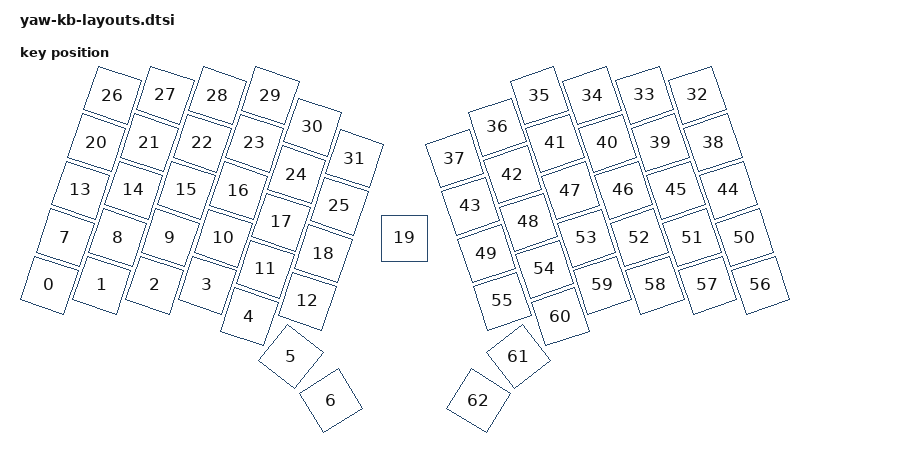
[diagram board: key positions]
#include <physical_layouts.dtsi>

/ {
    physical_layout0: physical_layout_0 {
        compatible = "zmk,physical-layout";
        display-name = "LAYOUT";

        kscan = <&kscan0>;
        transform = <&matrix_transform0>;

        keys  //                     w   h    x    y     rot    rx    ry
            = <&key_physical_attrs 100 100    0  380    1843    50   430>
            , <&key_physical_attrs 100 100  105  380    1843   155   430>
            , <&key_physical_attrs 100 100  211  380    1843   261   430>
            , <&key_physical_attrs 100 100  316  380    1843   366   431>
            , <&key_physical_attrs 100 100  400  443    1843   450   493>
            , <&key_physical_attrs 100 100  484  523    3844   534   573>
            , <&key_physical_attrs 100 100  564  611 (-3156)   614   661>
            , <&key_physical_attrs 100 100   32  285    1843    82   335>
            , <&key_physical_attrs 100 100  137  285    1843   187   335>
            , <&key_physical_attrs 100 100  242  285    1843   292   335>
            , <&key_physical_attrs 100 100  348  286    1843   398   336>
            , <&key_physical_attrs 100 100  432  348    1843   482   398>
            , <&key_physical_attrs 100 100  516  412    1843   566   462>
            , <&key_physical_attrs 100 100   63  190    1843   113   240>
            , <&key_physical_attrs 100 100  169  190    1843   219   240>
            , <&key_physical_attrs 100 100  274  190    1843   324   240>
            , <&key_physical_attrs 100 100  379  191    1843   429   241>
            , <&key_physical_attrs 100 100  464  254    1843   514   304>
            , <&key_physical_attrs 100 100  548  317    1843   598   367>
            , <&key_physical_attrs 100 100  711  286       0   761   336>
            , <&key_physical_attrs 100 100   95   95    1843   145   145>
            , <&key_physical_attrs 100 100  200   95    1843   250   145>
            , <&key_physical_attrs 100 100  306   96    1843   356   146>
            , <&key_physical_attrs 100 100  411   96    1843   461   146>
            , <&key_physical_attrs 100 100  495  159    1843   545   209>
            , <&key_physical_attrs 100 100  580  222    1843   630   272>
            , <&key_physical_attrs 100 100  127    0    1843   176    50>
            , <&key_physical_attrs 100 100  232    0    1843   282    50>
            , <&key_physical_attrs 100 100  337    1    1843   387    51>
            , <&key_physical_attrs 100 100  442    1    1843   492    51>
            , <&key_physical_attrs 100 100  527   64    1843   577   114>
            , <&key_physical_attrs 100 100  611  127    1843   661   177>
            , <&key_physical_attrs 100 100 1296    0 (-1843)  1346    50>
            , <&key_physical_attrs 100 100 1191    0 (-1843)  1241    50>
            , <&key_physical_attrs 100 100 1086    1 (-1843)  1136    51>
            , <&key_physical_attrs 100 100  980    1 (-1843)  1030    51>
            , <&key_physical_attrs 100 100  896   64 (-1843)   946   114>
            , <&key_physical_attrs 100 100  811  127 (-1843)   861   177>
            , <&key_physical_attrs 100 100 1328   95 (-1843)  1378   145>
            , <&key_physical_attrs 100 100 1222   95 (-1843)  1272   145>
            , <&key_physical_attrs 100 100 1117   96 (-1843)  1167   146>
            , <&key_physical_attrs 100 100 1012   96 (-1843)  1062   146>
            , <&key_physical_attrs 100 100  927  159 (-1843)   977   209>
            , <&key_physical_attrs 100 100  843  222 (-1843)   893   272>
            , <&key_physical_attrs 100 100 1359  190 (-1843)  1409   240>
            , <&key_physical_attrs 100 100 1254  190 (-1843)  1304   240>
            , <&key_physical_attrs 100 100 1149  190 (-1843)  1199   240>
            , <&key_physical_attrs 100 100 1043  191 (-1843)  1093   241>
            , <&key_physical_attrs 100 100  959  254 (-1843)  1009   304>
            , <&key_physical_attrs 100 100  875  317 (-1843)   925   367>
            , <&key_physical_attrs 100 100 1391  285 (-1843)  1441   335>
            , <&key_physical_attrs 100 100 1286  285 (-1843)  1336   335>
            , <&key_physical_attrs 100 100 1180  285 (-1843)  1230   335>
            , <&key_physical_attrs 100 100 1075  286 (-1843)  1125   336>
            , <&key_physical_attrs 100 100  991  348 (-1843)  1041   398>
            , <&key_physical_attrs 100 100  906  412 (-1843)   956   462>
            , <&key_physical_attrs 100 100 1423  380 (-1843)  1473   430>
            , <&key_physical_attrs 100 100 1317  380 (-1843)  1367   430>
            , <&key_physical_attrs 100 100 1212  380 (-1843)  1262   430>
            , <&key_physical_attrs 100 100 1107  380 (-1843)  1157   431>
            , <&key_physical_attrs 100 100 1022  443 (-1843)  1072   493>
            , <&key_physical_attrs 100 100  939  523 (-3844)   989   573>
            , <&key_physical_attrs 100 100  859  611    3156   909   661>
            ;
    };
};


&layouts_position_map {
    yaw_posmap: yaw_map {
        physical-layout = <&physical_layout0>;
        positions
            = <26 27 28 29 30 31       37 36 35 34 33 32>
            , <20 21 22 23 24 25       26 27 28 29 30 31>
            , <13 14 15 16 17 18   19  49 48 47 46 45 44>
            , < 7  8  9 10 11 12       55 54 53 52 51 50>
            , < 0  1  2  3  4  5  6 62 61 60 59 58 57 56>;
    };
};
